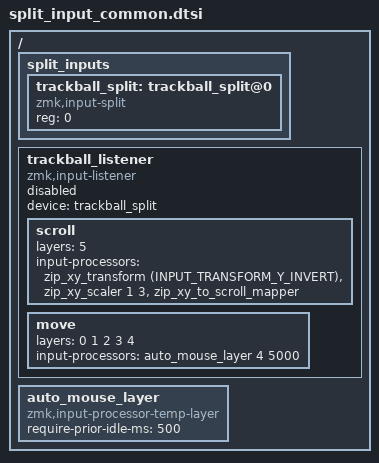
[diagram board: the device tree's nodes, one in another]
#include <dt-bindings/zmk/input_transform.h>
#include <input/processors.dtsi>

/ {
  split_inputs {
    #address-cells = <1>;
    #size-cells = <0>;

    trackball_split: trackball_split@0 {
      compatible = "zmk,input-split";
      reg = <0>;
    };
  };

  trackball_listener: trackball_listener {
    compatible = "zmk,input-listener";
    status = "disabled";
    device = <&trackball_split>;

    scroll {
      layers = <5>;
      input-processors = <&zip_xy_transform (INPUT_TRANSFORM_Y_INVERT)>, <&zip_xy_scaler 1 3>, <&zip_xy_to_scroll_mapper>;
    };

    move {
      layers = <0 1 2 3 4>;
      input-processors = <&auto_mouse_layer 4 5000>;
    };
  };

  auto_mouse_layer: auto_mouse_layer {
    compatible = "zmk,input-processor-temp-layer";
    #input-processor-cells = <2>;
    require-prior-idle-ms = <500>;
  };
};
